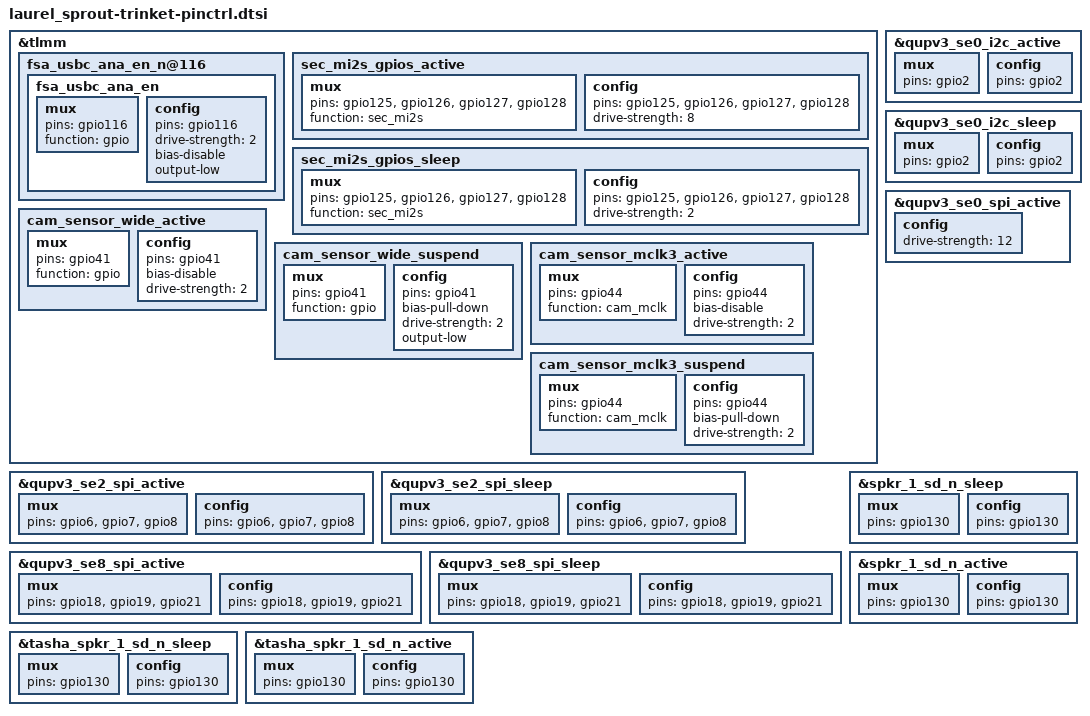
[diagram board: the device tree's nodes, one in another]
&tlmm {
	/delete-node/ fsa_usbc_ana_en_n@124;
	fsa_usbc_ana_en_n@116 {
		fsa_usbc_ana_en: fsa_usbc_ana_en {
			mux {
				pins = "gpio116";
				function = "gpio";
			};

			config {
				pins = "gpio116";
				drive-strength = <2>;
				bias-disable;
				output-low;
			};
		};
	};
	/delete-node/ cdc_dmic01_clk_active;
	/delete-node/ cdc_dmic01_clk_sleep;
	/delete-node/ cdc_dmic01_data_active;
	/delete-node/ cdc_dmic01_data_sleep;
	/delete-node/ cdc_dmic23_clk_active;
	/delete-node/ cdc_dmic23_clk_sleep;
	/delete-node/ cdc_dmic23_data_active;
	/delete-node/ cdc_dmic23_data_sleep;

	sec_mi2s_gpios_active: sec_mi2s_gpios_active {
		mux {
			pins = "gpio125", "gpio126", "gpio127", "gpio128";
			function = "sec_mi2s";
		};

		config {
			pins = "gpio125", "gpio126", "gpio127", "gpio128";
			drive-strength = <8>;
		};
	};

	sec_mi2s_gpios_sleep: sec_mi2s_gpios_sleep {
		mux {
			pins = "gpio125", "gpio126", "gpio127", "gpio128";
			function = "sec_mi2s";
		};

		config {
			pins = "gpio125", "gpio126", "gpio127", "gpio128";
			drive-strength = <2>;
		};
	};

	cam_sensor_wide_active: cam_sensor_wide_active {
		/* RESET  */
		mux {
			pins = "gpio41";
			function = "gpio";
		};

		config {
			pins = "gpio41";
			bias-disable; /* No PULL */
			drive-strength = <2>; /* 2 MA */
		};
	};

	cam_sensor_wide_suspend: cam_sensor_wide_suspend {
		/* RESET */
		mux {
			pins = "gpio41";
			function = "gpio";
		};

		config {
			pins = "gpio41";
			bias-pull-down; /* PULL DOWN */
			drive-strength = <2>; /* 2 MA */
			output-low;
		};
	};

	cam_sensor_mclk3_active: cam_sensor_mclk3_active {
		/* MCLK1 */
		mux {
			pins = "gpio44";
			function = "cam_mclk";
		};

		config {
			pins = "gpio44";
			bias-disable; /* No PULL */
			drive-strength = <2>; /* 2 MA */
		};
	};

	cam_sensor_mclk3_suspend: cam_sensor_mclk3_suspend {
		/* MCLK1 */
		mux {
			pins = "gpio44";
			function = "cam_mclk";
		};

		config {
			pins = "gpio44";
			bias-pull-down; /* PULL DOWN */
			drive-strength = <2>; /* 2 MA */
		};
	};
};

&qupv3_se0_i2c_active {
	mux {
		pins = "gpio2";
	};
	config {
		pins = "gpio2";
	};
};

&qupv3_se0_i2c_sleep {
	mux {
		pins = "gpio2";
	};
	config {
		pins = "gpio2";
	};
};

&qupv3_se0_spi_active {
	config {
		drive-strength = <12>;
	};
};

&qupv3_se2_spi_active {
	mux {
		pins = "gpio6", "gpio7", "gpio8";
	};
	config {
		pins = "gpio6", "gpio7", "gpio8";
	};
};
&qupv3_se2_spi_sleep {
	mux {
		pins = "gpio6", "gpio7", "gpio8";
	};
	config {
		pins = "gpio6", "gpio7", "gpio8";
	};
};

&qupv3_se8_spi_active {
	mux {
		pins = "gpio18", "gpio19", "gpio21";
	};
	config {
		pins = "gpio18", "gpio19", "gpio21";
	};
};

&qupv3_se8_spi_sleep {
	mux {
		pins = "gpio18", "gpio19", "gpio21";
	};
	config {
		pins = "gpio18", "gpio19", "gpio21";
	};
};

&spkr_1_sd_n_sleep {
	mux {
		pins = "gpio130";
	};
	config {
		pins = "gpio130";
	};
};
&spkr_1_sd_n_active {
	mux {
		pins = "gpio130";
	};
	config {
		pins = "gpio130";
	};
};

&tasha_spkr_1_sd_n_sleep {
	mux {
		pins = "gpio130";
	};
	config {
		pins = "gpio130";
	};
};

&tasha_spkr_1_sd_n_active {
	mux {
		pins = "gpio130";
	};
	config {
		pins = "gpio130";
	};
};
